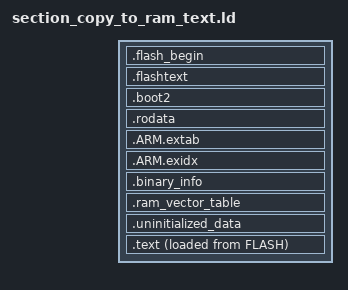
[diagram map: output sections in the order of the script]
SECTIONS
{
       /* On Arm, the bootrom expects a VT at the start of the
       image by default; on RISC-V, the default is to enter the image at its
       lowest address, so an IMAGE_DEF item is required to specify the
       nondefault entry point. */

    .flash_begin : {
        __flash_binary_start = .;
    } > FLASH

    /* The bootrom will enter the image at the point indicated in your
       IMAGE_DEF, which is usually the reset handler of your vector table.

       The debugger will use the ELF entry point, which is the _entry_point
       symbol, and in our case is *different from the bootrom's entry point.*
       This is used to go back through the bootrom on debugger launches only,
       to perform the same initial flash setup that would be performed on a
       cold boot.
    */

    .flashtext : {
        __logical_binary_start = .;
        KEEP (*(.vectors))
        KEEP (*(.binary_info_header))
        __binary_info_header_end = .;
        KEEP (*(.embedded_block))
        __embedded_block_end = .;
        KEEP (*(.reset))
        . = ALIGN(4);
    } > FLASH

    /* Note the boot2 section is optional, and should be discarded if there is
       no reference to it *inside* the binary, as it is not called by the
       bootrom. (The bootrom performs a simple best-effort XIP setup and
       leaves it to the binary to do anything more sophisticated.) However
       there is still a size limit of 256 bytes, to ensure the boot2 can be
       stored in boot RAM.

       Really this is a "XIP setup function" -- the name boot2 is historic and
       refers to its dual-purpose on RP2040, where it also handled vectoring
       from the bootrom into the user image.
    */

    .boot2 : {
        __boot2_start__ = .;
        *(.boot2)
        __boot2_end__ = .;
    } > FLASH

    ASSERT(__boot2_end__ - __boot2_start__ <= 256,
        "ERROR: Pico second stage bootloader must be no more than 256 bytes in size")

    .rodata : {
        /* segments not marked as .flashdata are instead pulled into .data (in RAM) to avoid accidental flash accesses */
        *(SORT_BY_ALIGNMENT(SORT_BY_NAME(.flashdata*)))
        . = ALIGN(4);
    } > FLASH

    .ARM.extab :
    {
        *(.ARM.extab* .gnu.linkonce.armextab.*)
    } > FLASH

    __exidx_start = .;
    .ARM.exidx :
    {
        *(.ARM.exidx* .gnu.linkonce.armexidx.*)
    } > FLASH
    __exidx_end = .;

    /* Machine inspectable binary information */
    . = ALIGN(4);
    __binary_info_start = .;
    .binary_info :
    {
        KEEP(*(.binary_info.keep.*))
        *(.binary_info.*)
    } > FLASH
    __binary_info_end = .;
    . = ALIGN(4);

    /* Vector table goes first in RAM, to avoid large alignment hole */
    .ram_vector_table (NOLOAD): {
        *(.ram_vector_table)
    } > RAM

    .uninitialized_data (NOLOAD): {
        . = ALIGN(4);
        *(.uninitialized_data*)
    } > RAM

    .text : {
        __ram_text_start__ = .;
        *(.init)
        *(.text*)
        *(.fini)
        /* Pull all c'tors into .text */
        *crtbegin.o(.ctors)
        *crtbegin?.o(.ctors)
        *(EXCLUDE_FILE(*crtend?.o *crtend.o) .ctors)
        *(SORT(.ctors.*))
        *(.ctors)
        /* Followed by destructors */
        *crtbegin.o(.dtors)
        *crtbegin?.o(.dtors)
        *(EXCLUDE_FILE(*crtend?.o *crtend.o) .dtors)
        *(SORT(.dtors.*))
        *(.dtors)

        *(.eh_frame*)
        . = ALIGN(4);
        __ram_text_end__ = .;
    } > RAM AT> FLASH
    __ram_text_source__ = LOADADDR(.text);
    . = ALIGN(4);
}
